# ATmega3250PA register map
Vendor: Atmel; File version: 1.0
CPU: other r0p0, little endian, no MPU, no FPU, 4 interrupt priority bits
Registers are 8-bit, read-write, reset 0x0 unless marked. A register's access mark holds for its fields unless they carry their own. Offsets are from the block's base; [hi:lo] are bit positions.

## PORTA — I/O Port
Base 0x00800020
0x00 PINA — Port A Input Pins (read-only for debugger)
0x01 DDRA — Port A Data Direction Register
0x02 PORTA — Port A Data Register

## PORTB — I/O Port
Base 0x00800023
0x00 PINB — Port B Input Pins (read-only for debugger)
0x01 DDRB — Port B Data Direction Register
0x02 PORTB — Port B Data Register

## PORTC — I/O Port
Base 0x00800026
0x00 PINC — Port C Input Pins (read-only for debugger)
0x01 DDRC — Port C Data Direction Register
0x02 PORTC — Port C Data Register

## PORTD — I/O Port
Base 0x00800029
0x00 PIND — Port D Input Pins (read-only for debugger)
0x01 DDRD — Port D Data Direction Register
0x02 PORTD — Port D Data Register

## PORTE — I/O Port
Base 0x0080002C
0x00 PINE — Input Pins, Port E (read-only for debugger)
0x01 DDRE — Data Direction Register, Port E
0x02 PORTE — Data Register, Port E

## PORTF — I/O Port
Base 0x0080002F
0x00 PINF — Input Pins, Port F (read-only for debugger)
0x01 DDRF — Data Direction Register, Port F
0x02 PORTF — Data Register, Port F

## PORTG — I/O Port
Base 0x00800032
0x00 PING — Port G Input Pins (read-only for debugger)
0x01 DDRG — Port G Data Direction Register
0x02 PORTG — Port G Data Register

## PORTH — I/O Port
Base 0x008000D8
0x00 PINH — PORT H Input Pins
0x01 DDRH — PORT H Data Direction Register
0x02 PORTH — PORT H Data Register

## PORTJ — I/O Port
Base 0x008000DB
0x00 PINJ — PORT J Input Pins
0x01 DDRJ — PORT J Data Direction Register
0x02 PORTJ — PORT J Data Register

## SPI — Serial Peripheral Interface
Base 0x0080004C
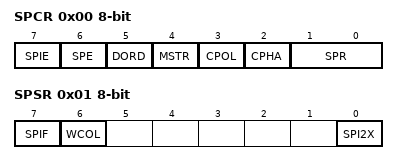
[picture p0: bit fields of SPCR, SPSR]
0x00 SPCR — SPI Control Register
  [7] SPIE — SPI Interrupt Enable
  [6] SPE — SPI Enable
  [5] DORD — Data Order
  [4] MSTR — Master/Slave Select
  [3] CPOL — Clock polarity
  [2] CPHA — Clock Phase
  [1:0] SPR — SPI Clock Rate Selects
    0=FOSC_4; 1=FOSC_16; 3=FOSC_128
0x01 SPSR — SPI Status Register (read-only for debugger)
  [7] SPIF — SPI Interrupt Flag
  [6] WCOL — Write Collision Flag
  [0] SPI2X — Double SPI Speed Bit
0x02 SPDR — SPI Data Register (write-only for debugger)

## TC0 — Timer/Counter, 8-bit
Base 0x00800035
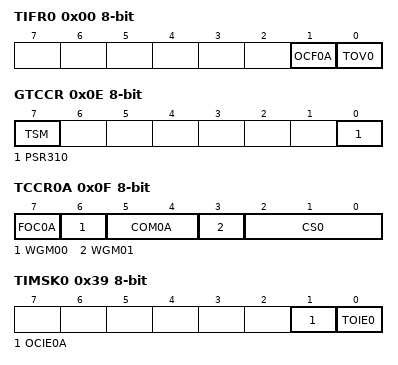
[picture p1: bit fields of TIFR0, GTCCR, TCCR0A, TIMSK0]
0x00 TIFR0 — Timer/Counter0 Interrupt Flag register (read-only for debugger)
  [1] OCF0A — Timer/Counter0 Output Compare Flag 0
  [0] TOV0 — Timer/Counter0 Overflow Flag
0x0E GTCCR — General Timer/Control Register
  [7] TSM — Timer/Counter Synchronization Mode
  [0] PSR310 — Prescaler Reset Timer/Counter1 and Timer/Counter0
0x0F TCCR0A — Timer/Counter0 Control Register
  [7] FOC0A — Force Output Compare
  [6] WGM00 — Waveform Generation Mode 0
    0=NORMAL; 1=CTC
  [5:4] COM0A — Compare Match Output Modes
  [3] WGM01 — Waveform Generation Mode 1
  [2:0] CS0 — Clock Selects
    0=NO_CLOCK_SOURCE_STOPPED; 1=RUNNING_NO_PRESCALING; 2=RUNNING_CLK_8; 3=RUNNING_CLK_64; 4=RUNNING_CLK_256; 5=RUNNING_CLK_1024; 6=RUNNING_EXTCLK_TN_FALLING_EDGE; 7=RUNNING_EXTCLK_TN_RISING_EDGE
0x11 TCNT0 — Timer/Counter0
0x12 OCR0A — Timer/Counter0 Output Compare Register
0x39 TIMSK0 — Timer/Counter0 Interrupt Mask Register
  [1] OCIE0A — Timer/Counter0 Output Compare Match Interrupt Enable
  [0] TOIE0 — Timer/Counter0 Overflow Interrupt Enable

## TC1 — Timer/Counter, 16-bit
Base 0x00800036
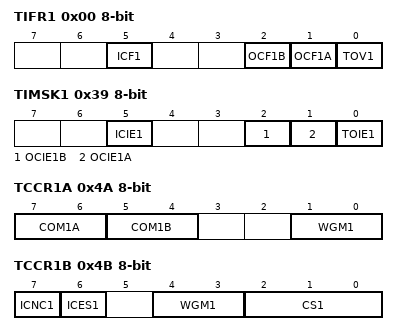
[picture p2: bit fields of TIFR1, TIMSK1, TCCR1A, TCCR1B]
0x00 TIFR1 — Timer/Counter1 Interrupt Flag register (read-only for debugger)
  [5] ICF1 — Input Capture Flag 1
  [2] OCF1B — Output Compare Flag 1B
  [1] OCF1A — Output Compare Flag 1A
  [0] TOV1 — Timer/Counter1 Overflow Flag
0x39 TIMSK1 — Timer/Counter1 Interrupt Mask Register
  [5] ICIE1 — Timer/Counter1 Input Capture Interrupt Enable
  [2] OCIE1B — Timer/Counter1 Output Compare B Match Interrupt Enable
  [1] OCIE1A — Timer/Counter1 Output Compare A Match Interrupt Enable
  [0] TOIE1 — Timer/Counter1 Overflow Interrupt Enable
0x4A TCCR1A — Timer/Counter1 Control Register A
  [7:6] COM1A — Compare Output Mode 1A, bits
  [5:4] COM1B — Compare Output Mode 1B, bits
  [1:0] WGM1 — Waveform Generation Mode
0x4B TCCR1B — Timer/Counter1 Control Register B
  [7] ICNC1 — Input Capture 1 Noise Canceler
  [6] ICES1 — Input Capture 1 Edge Select
  [4:3] WGM1 — Waveform Generation Mode
  [2:0] CS1 — Prescaler source of Timer/Counter 1
    0=NO_CLOCK_SOURCE_STOPPED; 1=RUNNING_NO_PRESCALING; 2=RUNNING_CLK_8; 3=RUNNING_CLK_64; 4=RUNNING_CLK_256; 5=RUNNING_CLK_1024; 6=RUNNING_EXTCLK_TN_FALLING_EDGE; 7=RUNNING_EXTCLK_TN_RISING_EDGE
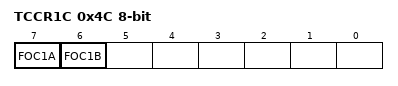
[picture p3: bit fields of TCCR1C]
0x4C TCCR1C — Timer/Counter 1 Control Register C
  [7] FOC1A — Force Output Compare 1A
  [6] FOC1B — Force Output Compare 1B
0x4E TCNT1 16-bit (reset mask 0xFF) — Timer/Counter1 Bytes
0x50 ICR1 16-bit (reset mask 0xFF) — Timer/Counter1 Input Capture Register Bytes
0x52 OCR1A 16-bit (reset mask 0xFF) — Timer/Counter1 Output Compare Register A Bytes
0x54 OCR1B 16-bit (reset mask 0xFF) — Timer/Counter1 Output Compare Register B Bytes
